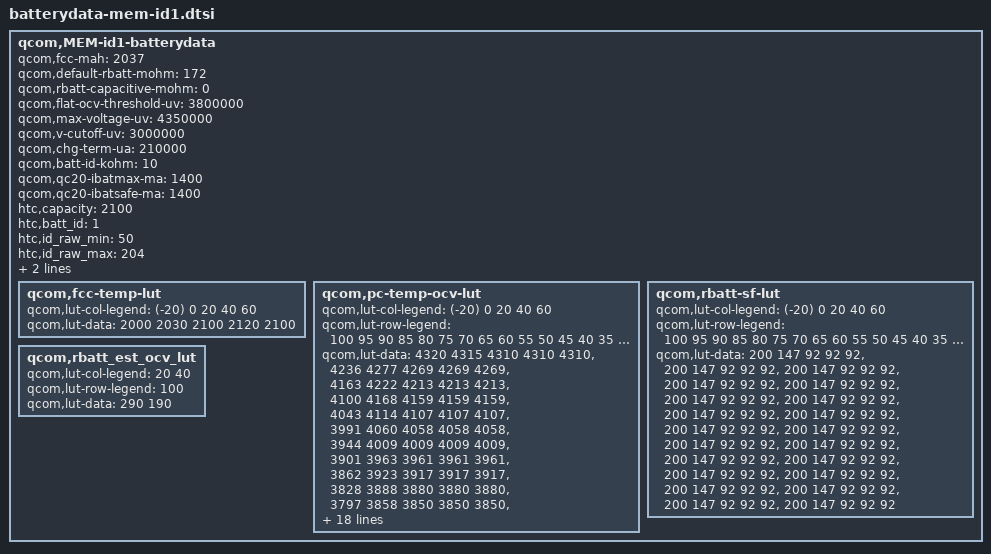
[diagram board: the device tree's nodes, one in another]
qcom,MEM-id1-batterydata {
	qcom,fcc-mah = <2037>;
	qcom,default-rbatt-mohm = <172>;
	qcom,rbatt-capacitive-mohm = <0>;
	qcom,flat-ocv-threshold-uv = <3800000>;
	qcom,max-voltage-uv = <4350000>;
	qcom,v-cutoff-uv = <3000000>;
	qcom,chg-term-ua = <210000>;
	qcom,batt-id-kohm = <10>;
	qcom,qc20-ibatmax-ma = <1400>;
	qcom,qc20-ibatsafe-ma = <1400>;
	htc,capacity = <2100>;
	htc,batt_id = <1>;
	htc,id_raw_min = <50>;
	htc,id_raw_max = <204>;
	htc,type = <1>;
	htc,model_name = "B0P6B100";

	qcom,fcc-temp-lut {
		qcom,lut-col-legend = <(-20) 0 20 40 60>;
		qcom,lut-data = <2000 2030 2100 2120 2100>;
	};

	qcom,pc-temp-ocv-lut {
		qcom,lut-col-legend = <(-20) 0 20 40 60>;
		qcom,lut-row-legend = <100 95 90 85 80 75 70 65 60 55 50 45 40 35 30 25 20 15 10 9 8 7 6 5 4 3 2 1 0>;
		qcom,lut-data = <4320 4315 4310 4310 4310>,
				<4236 4277 4269 4269 4269>,
				<4163 4222 4213 4213 4213>,
				<4100 4168 4159 4159 4159>,
				<4043 4114 4107 4107 4107>,
				<3991 4060 4058 4058 4058>,
				<3944 4009 4009 4009 4009>,
				<3901 3963 3961 3961 3961>,
				<3862 3923 3917 3917 3917>,
				<3828 3888 3880 3880 3880>,
				<3797 3858 3850 3850 3850>,
				<3774 3833 3827 3827 3827>,
				<3749 3809 3807 3807 3807>,
				<3724 3789 3790 3790 3790>,
				<3697 3771 3773 3773 3773>,
				<3666 3753 3751 3751 3751>,
				<3658 3735 3731 3731 3731>,
				<3623 3708 3704 3704 3704>,
				<3568 3683 3680 3680 3680>,
				<3538 3650 3672 3672 3672>,
				<3504 3612 3668 3668 3668>,
				<3461 3565 3659 3659 3659>,
				<3418 3518 3608 3608 3608>,
				<3354 3448 3577 3577 3577>,
				<3336 3403 3519 3519 3519>,
				<3317 3358 3461 3461 3461>,
				<3291 3296 3381 3381 3381>,
				<3251 3197 3254 3254 3254>,
				<3169 3000 3000 3000 3000>;
	};

	qcom,rbatt-sf-lut {
		qcom,lut-col-legend = <(-20) 0 20 40 60>;
		qcom,lut-row-legend = <100 95 90 85 80 75 70 65 60 55 50 45 40 35 30 25 20 15 10 5 0>;
		qcom,lut-data = <200 147 92 92 92>,
				<200 147 92 92 92>,
				<200 147 92 92 92>,
				<200 147 92 92 92>,
				<200 147 92 92 92>,
				<200 147 92 92 92>,
				<200 147 92 92 92>,
				<200 147 92 92 92>,
				<200 147 92 92 92>,
				<200 147 92 92 92>,
				<200 147 92 92 92>,
				<200 147 92 92 92>,
				<200 147 92 92 92>,
				<200 147 92 92 92>,
				<200 147 92 92 92>,
				<200 147 92 92 92>,
				<200 147 92 92 92>,
				<200 147 92 92 92>,
				<200 147 92 92 92>,
				<200 147 92 92 92>,
				<200 147 92 92 92>;
	};

	qcom,rbatt_est_ocv_lut {
		qcom,lut-col-legend = <20 40>;
		qcom,lut-row-legend = <100>;
		qcom,lut-data = <290 190>;
	};
};
